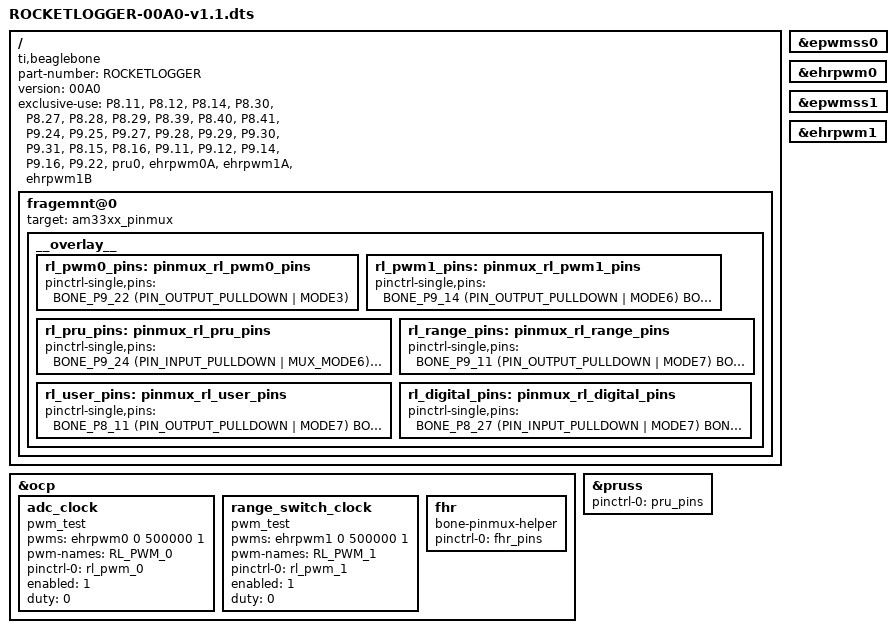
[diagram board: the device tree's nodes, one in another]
/*
 * Device tree for the RocketLogger beaglebone cape.
 * Version for Linux kernel 4.1+
 */

/dts-v1/;
/plugin/;

#include <dt-bindings/board/am335x-bbw-bbb-base.h>
#include <dt-bindings/pinctrl/am33xx.h>

/ {
	compatible = "ti,beaglebone", "ti,beaglebone-green", "ti,beaglebone-black";

	/* board identification */
	part-number = "ROCKETLOGGER";
	version = "00A0";

	/* ressources used by the rocketlogger cape */
	exclusive-use =
	
    /* GPIO pins used */
		"P8.11",	/* LED pins */
		"P8.12",
		"P8.14",	/* Button pin */
		
		"P8.30",  /* Digital input buffer enable pin */
		"P8.27",  /* Digital input pins */
		"P8.28",
		"P8.29",
		"P8.39",
		"P8.40",
		"P8.41",
    
		"P9.24",	/* PRU controlled pins */
		"P9.25",
		"P9.27",
		"P9.28",
		"P9.29",
		"P9.30",
		"P9.31",
		"P8.15",
		"P8.16",
    
		"P9.11",  /* nForce high range pins */
		"P9.12",
		
		"P9.14",	/* PWM pins */
		"P9.16",
		"P9.22",
		
		/* Hardware blocks used */
		"pru0",     /* PRU for ADC control */
		"ehrpwm0A", /* EHRPWM0 for TODO: ??? */
		"ehrpwm1A", /* EHRPWM1 for TODO: ??? */
		"ehrpwm1B";
	
	/* Pin muxing */
	fragemnt@0 {
	  target = <&am33xx_pinmux>;
	  __overlay__ {
	    rl_pwm0_pins: pinmux_rl_pwm0_pins {
        pinctrl-single,pins = <
          BONE_P9_22 (PIN_OUTPUT_PULLDOWN | MODE3) /* ehrpwm0A pin configuration */
        >;
		  };

	    rl_pwm1_pins: pinmux_rl_pwm1_pins {
        pinctrl-single,pins = <
          BONE_P9_14 (PIN_OUTPUT_PULLDOWN | MODE6) /* ehrpwm1A pin configuration */
          BONE_P9_16 (PIN_OUTPUT_PULLDOWN | MODE6) /* ehrpwm1B pin configuration */
        >;
		  };
		  
		  rl_pru_pins: pinmux_rl_pru_pins {
        pinctrl-single,pins = <
          BONE_P9_24 (PIN_INPUT_PULLDOWN | MUX_MODE6) /* MISO1 pin configuration */
          BONE_P9_25 (PIN_OUTPUT | MUX_MODE5) /* START pin configuration */
          BONE_P9_27 (PIN_OUTPUT | MUX_MODE5) /* CS1 pin configuration */
          BONE_P9_28 (PIN_OUTPUT | MUX_MODE5) /* CS0 pin configuration */
          BONE_P9_29 (PIN_OUTPUT | MUX_MODE5) /* MOSI pin configuration */
          BONE_P9_30 (PIN_INPUT_PULLDOWN | MUX_MODE6) /* MISO0 pin configuration */
          BONE_P9_31 (PIN_OUTPUT | MUX_MODE5) /* SCLK pin configuration */
          BONE_P8_15 (PIN_INPUT_PULLUP | MUX_MODE6) /* DR1 pin configuration */
          BONE_P8_16 (PIN_INPUT_PULLUP | MUX_MODE6) /* DR0 pin configuration */
        >;
		  };
		  
		  rl_range_pins: pinmux_rl_range_pins {
        pinctrl-single,pins = <
          BONE_P9_11 (PIN_OUTPUT_PULLDOWN | MODE7) /* nForce high range 1 pin configuration */
          BONE_P9_12 (PIN_OUTPUT_PULLDOWN | MODE7) /* nForce high range 2 pin configuration */
        >;
		  };

		  rl_user_pins: pinmux_rl_user_pins {
        pinctrl-single,pins = <
          BONE_P8_11 (PIN_OUTPUT_PULLDOWN | MODE7) /* Status LED pin configuration, TODO: check register configuration */
          BONE_P8_12 (PIN_OUTPUT_PULLDOWN | MODE7) /* Error LED pin configuration, TODO: check register configuration */
          BONE_P8_14 (PIN_INPUT_PULLDOWN | MODE7) /* User button pin configuration, TODO: check register configuration */
        >;
		  };

		  rl_digital_pins: pinmux_rl_digital_pins {
        pinctrl-single,pins = <
          BONE_P8_27 (PIN_INPUT_PULLDOWN | MODE7) /* Digital input 3 pin configuration, TODO: check register configuration */
          BONE_P8_28 (PIN_INPUT_PULLDOWN | MODE7) /* Digital input 4 pin configuration, TODO: check register configuration */
          BONE_P8_29 (PIN_INPUT_PULLDOWN | MODE7) /* Digital input 5 pin configuration, TODO: check register configuration */
          BONE_P8_39 (PIN_INPUT_PULLDOWN | MODE7) /* Digital input 6 pin configuration, TODO: check register configuration */
          BONE_P8_40 (PIN_INPUT_PULLDOWN | MODE7) /* Digital input 1 pin configuration, TODO: check register configuration */
          BONE_P8_41 (PIN_INPUT_PULLDOWN | MODE7) /* Digital input 2 pin configuration, TODO: check register configuration */

          BONE_P8_30 (PIN_OUTPUT_PULLUP | MODE7) /* Digital input buffer enable pin configuration, TODO: check register configuration */
        >;
		  };
	  };
	};
	
	
	/* Enable EHRPWM0 and EHRPWM1 */
	fragment@10 {
		target = <&epwmss0>;
		__overlay__ {
			status = "okay";
		};
	};

	fragment@11 {
		target = <&ehrpwm0>;
		__overlay__ {
			status = "okay";
		};
	};
	
	fragment@12 {
		target = <&epwmss1>;
		__overlay__ {
			status = "okay";
		};
	};

	fragment@13 {
		target = <&ehrpwm1>;
		__overlay__ {
			status = "okay";
		};
	};

	
	/* Apply pins to EHRPWM-Modules */
	fragment@20 {
		target = <&ocp>;
		__overlay__ {
			adc_clock {
				compatible	= "pwm_test";
				pwms 		= <&ehrpwm0 0 500000 1>;
				pwm-names 	= "RL_PWM_0";
			    pinctrl-names	= "default";
			    pinctrl-0	= <&rl_pwm_0>;
				enabled		= <1>;
				duty		= <0>;
				status 		= "okay";
			};
		};
	};

	fragment@21 {
		target = <&ocp>;
		__overlay__ {
			range_switch_clock {
				compatible	= "pwm_test";
				pwms 		= <&ehrpwm1 0 500000 1>;
				pwm-names 	= "RL_PWM_1";
			    pinctrl-names	= "default";
			    pinctrl-0	= <&rl_pwm_1>;
				enabled		= <1>;
				duty		= <0>;
				status 		= "okay";
			};
		};
	};
	
	fragment@22 {  
		target = <&pruss>;  
		__overlay__ {  
			status = "okay";  
			pinctrl-names = "default";  
			pinctrl-0 = <&pru_pins>;  
		};  
	}; 
   
	fragment@23 {
		target = <&ocp>;
		__overlay__ {
			fhr {
				compatible = "bone-pinmux-helper";
				pinctrl-names = "default";
				pinctrl-0 = <&fhr_pins>;
				status = "okay";
            };
        };
    };
};
